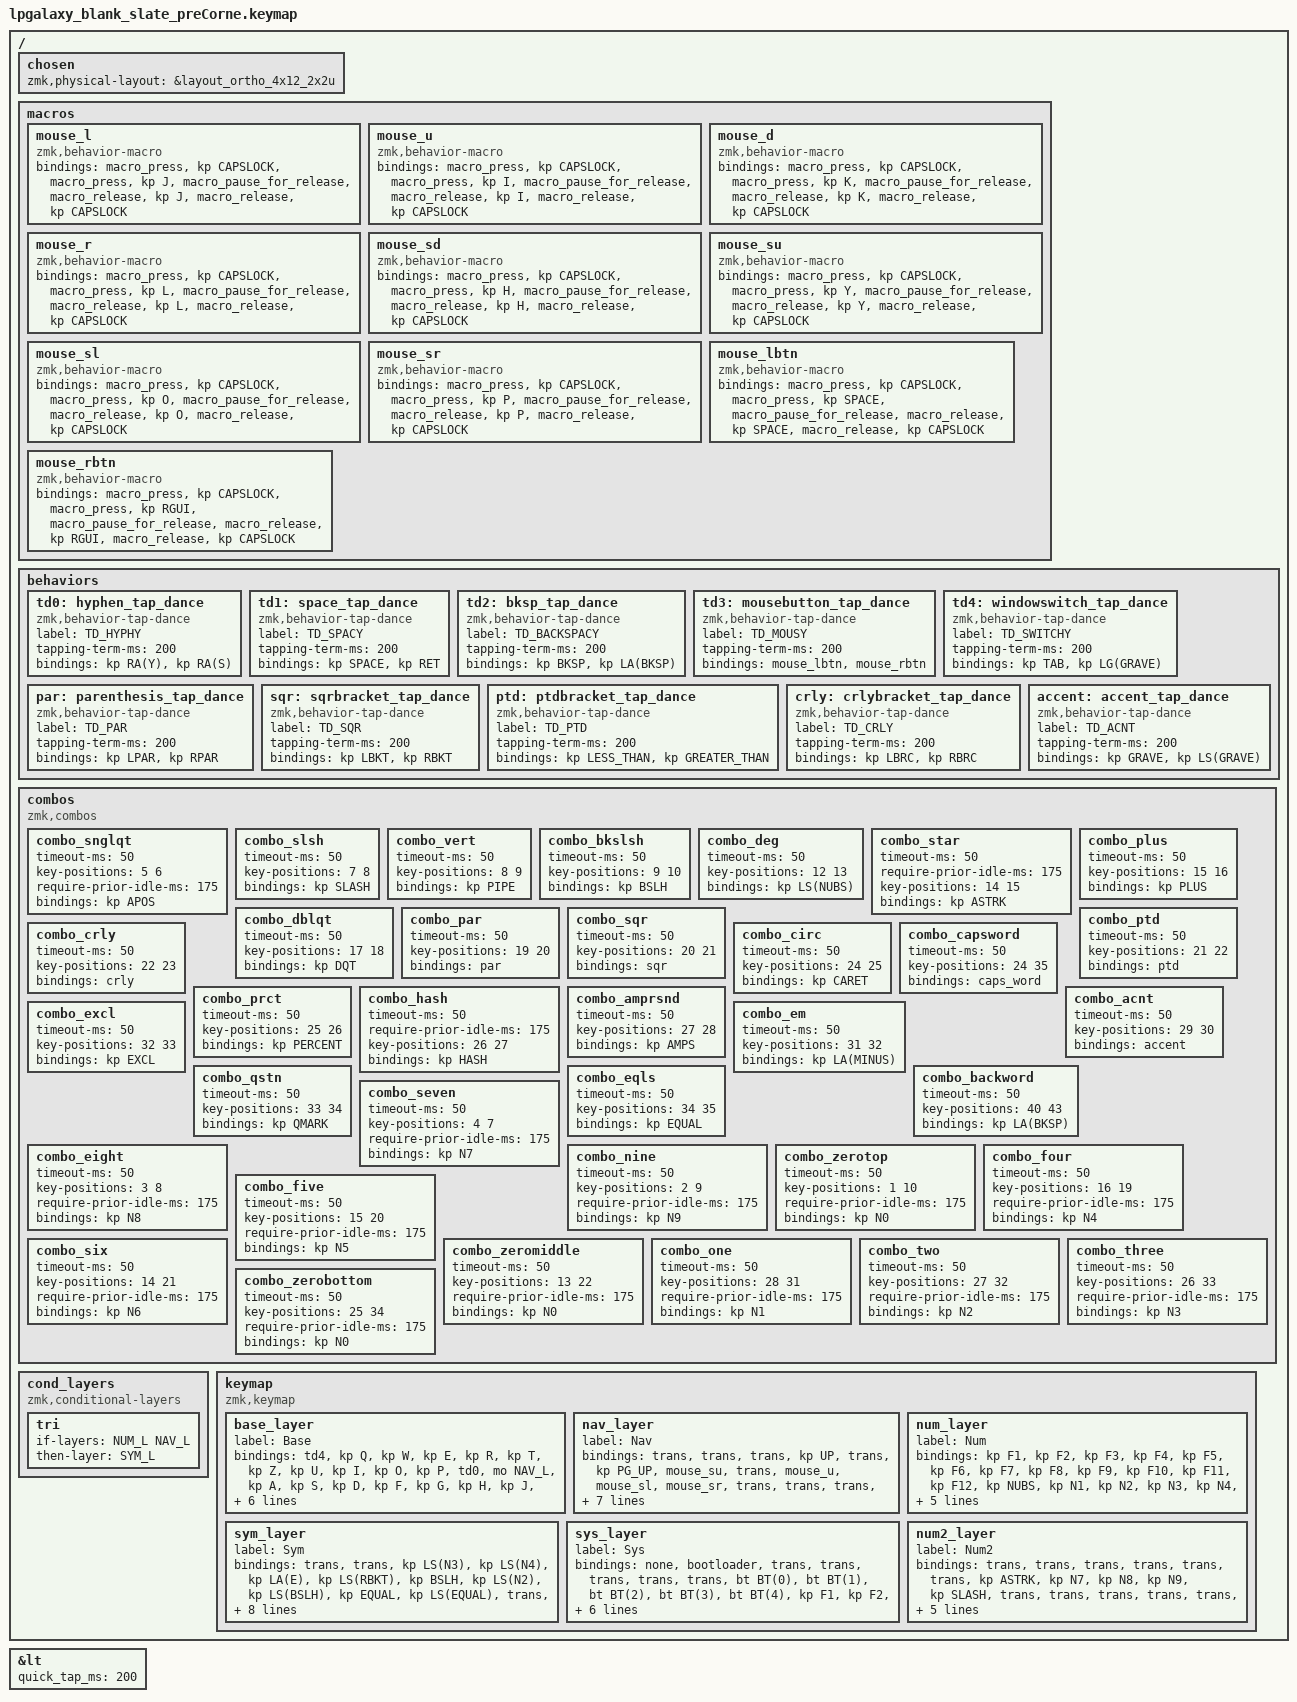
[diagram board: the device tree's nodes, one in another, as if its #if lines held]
/*
 * Copyright (c) 2022 Pete Johanson
 *
 * SPDX-License-Identifier: MIT
 */

// GLOBE as RA(ESC) via double tap + remapping in Karabiner / mouse pointer, scrolling and keys via remapping in Karabiner

#include <behaviors.dtsi>
#include <dt-bindings/zmk/keys.h>
#include <dt-bindings/zmk/bt.h>
#include <dt-bindings/zmk/outputs.h>

#define QWERTY_BASE 1

#define TBLE_ORTHO   1
// #define TBLE_MIT     1
// #define TBLE_DUAL_2U 1

#define NAV_L 1
#define NUM_L 2
#define SYM_L 3
#define SYS_L 4
#define NUM_R 5

// Using layer taps on thumbs, having quick tap as well helps w/ repeating space/backspace
&lt { quick_tap_ms = <200>; };

#define BT(n) BT_SEL n

/ {
    chosen {
       zmk,physical-layout =
#ifdef TBLE_DUAL_2U
                       &layout_ortho_4x12_2x2u;
#elif defined(TBLE_MIT)
                       &layout_ortho_4x12_1x2u;
#else
                       &layout_ortho_4x12_all1u;
#endif
    };

    macros {
        mouse_l: mouse_l {
            compatible = "zmk,behavior-macro";
            #binding-cells = <0>;
            bindings
                = <&macro_press &kp CAPSLOCK>
		, <&macro_press &kp J>
		, <&macro_pause_for_release>
		, <&macro_release &kp J>
                , <&macro_release &kp CAPSLOCK>
                ;
        };
	mouse_u: mouse_u {
            compatible = "zmk,behavior-macro";
            #binding-cells = <0>;
            bindings
                = <&macro_press &kp CAPSLOCK>
		, <&macro_press &kp I>
		, <&macro_pause_for_release>
		, <&macro_release &kp I>
                , <&macro_release &kp CAPSLOCK>
                ;
        };
	mouse_d: mouse_d {
            compatible = "zmk,behavior-macro";
            #binding-cells = <0>;
            bindings
                = <&macro_press &kp CAPSLOCK>
		, <&macro_press &kp K>
		, <&macro_pause_for_release>
		, <&macro_release &kp K>
                , <&macro_release &kp CAPSLOCK>
                ;
        };
	mouse_r: mouse_r {
            compatible = "zmk,behavior-macro";
            #binding-cells = <0>;
            bindings
                = <&macro_press &kp CAPSLOCK>
		, <&macro_press &kp L>
		, <&macro_pause_for_release>
		, <&macro_release &kp L>
                , <&macro_release &kp CAPSLOCK>
                ;
        };
	mouse_sd: mouse_sd {
            compatible = "zmk,behavior-macro";
            #binding-cells = <0>;
            bindings
                = <&macro_press &kp CAPSLOCK>
		, <&macro_press &kp H>
		, <&macro_pause_for_release>
		, <&macro_release &kp H>
                , <&macro_release &kp CAPSLOCK>
                ;
        };
	mouse_su: mouse_su {
            compatible = "zmk,behavior-macro";
            #binding-cells = <0>;
            bindings
                = <&macro_press &kp CAPSLOCK>
		, <&macro_press &kp Y>
		, <&macro_pause_for_release>
		, <&macro_release &kp Y>
                , <&macro_release &kp CAPSLOCK>
                ;
        };
	mouse_sl: mouse_sl {
            compatible = "zmk,behavior-macro";
            #binding-cells = <0>;
            bindings
                = <&macro_press &kp CAPSLOCK>
		, <&macro_press &kp O>
		, <&macro_pause_for_release>
		, <&macro_release &kp O>
                , <&macro_release &kp CAPSLOCK>
                ;
        };
	mouse_sr: mouse_sr {
            compatible = "zmk,behavior-macro";
            #binding-cells = <0>;
            bindings
                = <&macro_press &kp CAPSLOCK>
		, <&macro_press &kp P>
		, <&macro_pause_for_release>
		, <&macro_release &kp P>
                , <&macro_release &kp CAPSLOCK>
                ;
        };
	mouse_lbtn: mouse_lbtn {
            compatible = "zmk,behavior-macro";
            #binding-cells = <0>;
            bindings
                = <&macro_press &kp CAPSLOCK>
		, <&macro_press &kp SPACE>
		, <&macro_pause_for_release>
		, <&macro_release &kp SPACE>
                , <&macro_release &kp CAPSLOCK>
                ;
        };
	mouse_rbtn: mouse_rbtn {
            compatible = "zmk,behavior-macro";
            #binding-cells = <0>;
            bindings
                = <&macro_press &kp CAPSLOCK>
		, <&macro_press &kp RGUI>
		, <&macro_pause_for_release>
		, <&macro_release &kp RGUI>
                , <&macro_release &kp CAPSLOCK>
                ;
        };
    };
    
    behaviors {
	td0: hyphen_tap_dance {
		compatible = "zmk,behavior-tap-dance";
		label = "TD_HYPHY";
		#binding-cells = <0>;
		tapping-term-ms = <200>;
		bindings = <&kp RA(Y)>, <&kp RA(S)>;
	};
	td1: space_tap_dance {
		compatible = "zmk,behavior-tap-dance";
		label = "TD_SPACY";
		#binding-cells = <0>;
		tapping-term-ms = <200>;
		bindings = <&kp SPACE>, <&kp RET>;
	};
	td2: bksp_tap_dance {
		compatible = "zmk,behavior-tap-dance";
		label = "TD_BACKSPACY";
		#binding-cells = <0>;
		tapping-term-ms = <200>;
		bindings = <&kp BKSP>, <&kp LA(BKSP)>;
	};
	td3: mousebutton_tap_dance {
		compatible = "zmk,behavior-tap-dance";
		label = "TD_MOUSY";
		#binding-cells = <0>;
		tapping-term-ms = <200>;
		bindings = <&mouse_lbtn>, <&mouse_rbtn>;
	};
	td4: windowswitch_tap_dance {
		compatible = "zmk,behavior-tap-dance";
		label = "TD_SWITCHY";
		#binding-cells = <0>;
		tapping-term-ms = <200>;
		bindings = <&kp TAB>, <&kp LG(GRAVE)>;
	};
	par: parenthesis_tap_dance {
		compatible = "zmk,behavior-tap-dance";
		label = "TD_PAR";
		#binding-cells = <0>;
		tapping-term-ms = <200>;
		bindings = <&kp LPAR>, <&kp RPAR>;
	};
	sqr: sqrbracket_tap_dance {
		compatible = "zmk,behavior-tap-dance";
		label = "TD_SQR";
		#binding-cells = <0>;
		tapping-term-ms = <200>;
		bindings = <&kp LBKT>, <&kp RBKT>;
	};
	ptd: ptdbracket_tap_dance {
		compatible = "zmk,behavior-tap-dance";
		label = "TD_PTD";
		#binding-cells = <0>;
		tapping-term-ms = <200>;
		bindings = <&kp LESS_THAN>, <&kp GREATER_THAN>;
	};
	crly: crlybracket_tap_dance {
		compatible = "zmk,behavior-tap-dance";
		label = "TD_CRLY";
		#binding-cells = <0>;
		tapping-term-ms = <200>;
		bindings = <&kp LBRC>, <&kp RBRC>;
	};
	accent: accent_tap_dance {
		compatible = "zmk,behavior-tap-dance";
		label = "TD_ACNT";
		#binding-cells = <0>;
		tapping-term-ms = <200>;
		bindings = <&kp GRAVE>, <&kp LS(GRAVE)>;
	};
    };

    combos {
        compatible = "zmk,combos";
	combo_snglqt {
            timeout-ms = <50>;
            key-positions = <5 6>;
	    require-prior-idle-ms = <175>;
            bindings = <&kp APOS>;
        };
	combo_slsh {
            timeout-ms = <50>;
            key-positions = <7 8>;
            bindings = <&kp SLASH>;
        };
	combo_vert {
            timeout-ms = <50>;
            key-positions = <8 9>;
	    bindings = <&kp PIPE>;
        };
	combo_bkslsh {
            timeout-ms = <50>;
            key-positions = <9 10>;
            bindings = <&kp BSLH>;
        };
	combo_deg {
            timeout-ms = <50>;
            key-positions = <12 13>;
            bindings = <&kp LS(NUBS)>;
        };
	combo_star {
            timeout-ms = <50>;
	    require-prior-idle-ms = <175>;
            key-positions = <14 15>;
            bindings = <&kp ASTRK>;
        };
	combo_plus {
            timeout-ms = <50>;
            key-positions = <15 16>;
            bindings = <&kp PLUS>;
        };
	combo_dblqt {
            timeout-ms = <50>;
            key-positions = <17 18>;
            bindings = <&kp DQT>;
        };
	combo_par {
            timeout-ms = <50>;
            key-positions = <19 20>;
            bindings = <&par>;
        };
	combo_sqr {
            timeout-ms = <50>;
            key-positions = <20 21>;
            bindings = <&sqr>;
        };
	combo_ptd {
            timeout-ms = <50>;
            key-positions = <21 22>;
            bindings = <&ptd>;
        };
	combo_crly {
            timeout-ms = <50>;
            key-positions = <22 23>;
            bindings = <&crly>;
        };
	combo_circ {
            timeout-ms = <50>;
            key-positions = <24 25>;
            bindings = <&kp CARET>;
        };
	combo_capsword {
            timeout-ms = <50>;
            key-positions = <24 35>;
            bindings = <&caps_word>;
        };
	combo_prct {
            timeout-ms = <50>;
            key-positions = <25 26>;
            bindings = <&kp PERCENT>;
        };
	combo_hash {
            timeout-ms = <50>;
	    require-prior-idle-ms = <175>;
            key-positions = <26 27>;
            bindings = <&kp HASH>;
        };
	combo_amprsnd {
            timeout-ms = <50>;
            key-positions = <27 28>;
            bindings = <&kp AMPS>;
        };
	combo_acnt {
            timeout-ms = <50>;
            key-positions = <29 30>;
            bindings = <&accent>;
        };
	combo_em {
            timeout-ms = <50>;
            key-positions = <31 32>;
            bindings = <&kp LA(MINUS)>;
        };
	combo_excl {
            timeout-ms = <50>;
            key-positions = <32 33>;
            bindings = <&kp EXCL>;
        };
	combo_qstn {
            timeout-ms = <50>;
            key-positions = <33 34>;
            bindings = <&kp QMARK>;
        };
	combo_eqls {
            timeout-ms = <50>;
            key-positions = <34 35>;
            bindings = <&kp EQUAL>;
        };
	combo_backword {
            timeout-ms = <50>;
            key-positions = <40 43>;
            bindings = <&kp LA(BKSP)>;
        };
// numbers combos
	combo_seven {
            timeout-ms = <50>;
            key-positions = <4 7>;
	    require-prior-idle-ms = <175>;
            bindings = <&kp N7>;
        };
	combo_eight {
            timeout-ms = <50>;
            key-positions = <3 8>;
	    require-prior-idle-ms = <175>;
            bindings = <&kp N8>;
        };
	combo_nine {
            timeout-ms = <50>;
            key-positions = <2 9>;
	    require-prior-idle-ms = <175>;
            bindings = <&kp N9>;
        };
	combo_zerotop {
            timeout-ms = <50>;
            key-positions = <1 10>;
	    require-prior-idle-ms = <175>;
            bindings = <&kp N0>;
        };
	combo_four {
            timeout-ms = <50>;
            key-positions = <16 19>;
	    require-prior-idle-ms = <175>;
            bindings = <&kp N4>;
        };
	combo_five {
            timeout-ms = <50>;
            key-positions = <15 20>;
	    require-prior-idle-ms = <175>;
            bindings = <&kp N5>;
        };
	combo_six {
            timeout-ms = <50>;
            key-positions = <14 21>;
	    require-prior-idle-ms = <175>;
            bindings = <&kp N6>;
        };
	combo_zeromiddle {
            timeout-ms = <50>;
            key-positions = <13 22>;
	    require-prior-idle-ms = <175>;
            bindings = <&kp N0>;
        };
	combo_one {
            timeout-ms = <50>;
            key-positions = <28 31>;
	    require-prior-idle-ms = <175>;
            bindings = <&kp N1>;
        };
	combo_two {
            timeout-ms = <50>;
            key-positions = <27 32>;
	    require-prior-idle-ms = <175>;
            bindings = <&kp N2>;
        };
	combo_three {
            timeout-ms = <50>;
            key-positions = <26 33>;
	    require-prior-idle-ms = <175>;
            bindings = <&kp N3>;
        };
	combo_zerobottom {
            timeout-ms = <50>;
            key-positions = <25 34>;
	    require-prior-idle-ms = <175>;
            bindings = <&kp N0>;
        };
    };

// Conditional layer only when we have less thumb keys
#ifdef TBLE_DUAL_2U
    cond_layers {
        compatible = "zmk,conditional-layers";
	tri {
	    if-layers = <NUM_L NAV_L>;
	    then-layer = <SYM_L>;
        };
    };
#endif

    keymap {
        compatible = "zmk,keymap";

        base_layer {
            label = "Base";
            bindings = <
#ifdef QWERTY_BASE
 &td4       &kp Q      &kp W      &kp E       &kp R          &kp T          &kp Z            &kp U          &kp I       &kp O      &kp P         &td0
 &mo NAV_L  &kp A      &kp S      &kp D       &kp F          &kp G          &kp H            &kp J          &kp K       &kp L      &kp RA(P)	 &lt NAV_L RA(Q)
 &kp LSHFT  &kp Y      &kp X      &kp C       &kp V          &kp B          &kp N            &kp M          &kp COMMA   &kp DOT    &kp MINUS      &kp RSHIFT
#else
 &kp ESC    &kp Q      &kp W      &kp F       &kp P          &kp B          &kp J            &kp L          &kp U       &kp Y      &kp QUOT      &kp BKSP
 &kp TAB    &kp A      &kp R      &kp S       &kp T          &kp G          &kp M            &kp N          &kp E       &kp I      &kp O         &kp QUOT
 &kp LSHFT  &kp Z      &kp X      &kp C       &kp D          &kp V          &kp K            &kp H          &kp COMMA   &kp DOT    &kp SEMI      &kp RET
#endif
#ifdef TBLE_DUAL_2U
 &kp LCTRL  &kp LGUI   &kp LALT   &mo NAV_L         &shifty                        &kp SPACE                &mo NUM_L   &kp LALT   &kp RGUI      &kp RSHIFT
#elif defined(TBLE_MIT)
 &kp LCTRL  &mo SYM_L   &kp LGUI  &kp LALT    &mo NAV_L          &kp SPACE                   &mo NUM_L      &kp LEFT    &kp UP     &kp DOWN      &kp RIGHT
#else
 &mt RA(ESC) ESC    &kp LCTRL  &kp LALT   &kp LGUI    &kp BKSP   &mo NUM_L      &mo NUM_R         &td1      &kp RGUI    &kp RALT   &mo SYS_L      &kp RET
#endif
            >;
        };

        nav_layer {
            label = "Nav";
            bindings = <
&trans	   &trans     &trans     &kp UP      &trans          &kp PG_UP    &mouse_su     &trans         &mouse_u      &mouse_sl  &mouse_sr  &trans
&trans     &trans     &kp LEFT   &kp DOWN    &kp RIGHT       &kp PG_DN    &mouse_sd     &mouse_l       &mouse_d      &mouse_r   &kp RALT     &trans
&trans     &trans     &trans  	 &trans      &kp LG(LEFT)    &kp LG(RIGHT) &kp BKSP     &kp DEL        &trans        &trans     &trans     &trans
#ifdef TBLE_DUAL_2U
&trans  &trans        &trans     &trans              &trans                    &trans       &trans         &trans &trans &trans
#elif defined(TBLE_MIT)
&trans  &trans        &trans     &trans      &trans                &trans             &trans      &trans   &trans &trans &trans
#else
&trans     &trans     &trans     &trans      &mt LA(LSHIFT) BKSP          &kp HOME     &kp END     &td3         &trans      &trans     &trans     &trans
#endif
            >;
        };

        num_layer {
            label = "Num";
            bindings = <
&kp F1     &kp F2   	&kp F3 	&kp F4 	&kp F5    &kp F6   &kp F7    &kp F8     &kp F9    	  &kp F10      &kp F11    &kp F12
&kp NUBS   &kp N1	&kp N2 	&kp N3 	&kp N4    &kp N5   &kp N6    &kp N7     &kp N8      &kp N9       &kp N0     &kp NON_US_HASH
&trans     &trans	&trans 	&trans 	&trans    &trans   &trans    &trans     &trans      &trans       &trans     &trans
#ifdef TBLE_DUAL_2U
&trans  &trans       &trans     &kp N0              &trans                 &trans            &trans         &trans &trans &trans
#elif defined(TBLE_MIT)
&trans  &trans       &trans     &kp N0      &trans           &none            &trans        &kp DEL      &trans &trans &trans
#else
&trans     &trans       &trans  &trans  &trans    &none     &none     &trans    &trans      &trans 	 &trans     &kp GLOBE
#endif
            >;
        };

        sym_layer {
            label = "Sym";
            bindings = <
&trans     &trans     	 &kp LS(N3)   &kp LS(N4)    &kp LA(E)     &kp LS(RBKT)   &kp BSLH       &kp LS(N2) 	&kp LS(BSLH) 	&kp EQUAL    	&kp LS(EQUAL)   &trans
&trans     &kp LA(N8) 	 &kp LA(N9)   &kp GRAVE     &kp LS(GRAVE) &kp LS(N1)     &kp LS(NUHS)   &kp LS(N8)   	&kp LS(N9)  	&kp LA(N5)   	&kp LA(N6) 	&trans
&trans     &kp LS(N5)  	 &trans       &trans        &kp RBKT      &kp LS(N6) 	 &kp LA(SLASH)  &kp LS(N7)    	&kp LA(N7)  	&kp LA(LS(N7)) 	&kp LS(N0)     	&trans
#ifdef TBLE_DUAL_2U
&trans &trans        &trans     &kp RPAR                &trans                    &trans       &trans         &trans &trans &trans
#elif defined(TBLE_MIT)
&trans &trans        &trans     &kp RPAR        &trans                &trans             &trans      &trans   &trans &trans &trans
#else
&trans     &trans     &trans  	&trans    &trans     &trans      &trans     &trans   &trans     &trans       &trans     &trans
#endif
            >;
        };

        sys_layer {
            label = "Sys";
            bindings = <
&none	   &bootloader  &trans 	&trans 	&trans    &trans   &trans    &bt BT(0)  &bt BT(1)   &bt BT(2)    &bt BT(3)  &bt BT(4)
&kp F1     &kp F2   	&kp F3 	&kp F4 	&kp F5    &kp F6   &kp F7    &kp F8     &kp F9      &kp F10      &kp F11    &kp F12
&trans     &trans	&trans 	&trans 	&trans    &trans   &trans    &bt BT_CLR &trans      &trans       &trans     &trans
#ifdef TBLE_DUAL_2U
&trans  &trans       &trans     &kp N0              &trans                 &trans            &trans         &trans &trans &trans
#elif defined(TBLE_MIT)
&trans  &trans       &trans     &kp N0      &trans           &none            &trans        &kp DEL      &trans &trans &trans
#else
&sys_reset     &trans       &trans  &trans  &trans    &none     &none     &trans    &trans      &trans 	 &trans     &none
#endif
            >;
        };

num2_layer {
            label = "Num2";
            bindings = <
&trans     &trans   	&trans 	&trans 	&trans    &trans   &kp ASTRK    &kp N7     &kp N8      &kp N9       &kp SLASH  &trans
&trans     &trans	&trans 	&trans 	&trans    &trans   &kp MINUS  	&kp N4     &kp N5      &kp N6       &kp N0     &trans
&trans     &trans	&trans 	&trans 	&trans    &trans   &kp PLUS    	&kp N1     &kp N2      &kp N3       &kp EQUAL  &trans
#ifdef TBLE_DUAL_2U
&trans  &trans       &trans     &trans              &trans                 &trans            &trans         &trans &trans &trans
#elif defined(TBLE_MIT)
&trans  &trans       &trans     &trans      &trans           &trans            &trans        &trans      &trans &trans &trans
#else
&trans     &trans       &trans  &trans  &trans    &none     &none     &trans    &trans      &trans 	 &trans     &trans
#endif
            >;
        };

    };
};
